# fpb register map
Vendor: Texas Instruments
Peripheral module from a debugger description file (folder MSP432).
Registers are 32-bit, read-write, no defined reset value unless marked. A register's access mark holds for its fields unless they carry their own. Offsets are as the file gives them; lines under a group give offsets from that group; [hi:lo] are bit positions; {n}, {i} and the like mark numbered series; 'fields as' and 'values as' point back to an identical list; <NAME> marks a mode.

## FPB
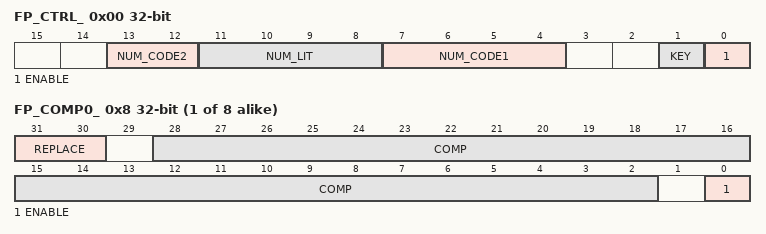
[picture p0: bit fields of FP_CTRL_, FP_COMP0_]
0x00 FP_CTRL_ — Flash Patch Control Register
  [13:12] NUM_CODE2 — Number of full banks of code comparators, sixteen comparators p
  [11:8] NUM_LIT — Number of literal slots field.
    0=NUM_LIT__0 (no literal slots); 2=NUM_LIT__2 (two literal slots)
  [7:4] NUM_CODE1 — Number of code slots field.
    0=NUM_CODE1__0 (no code slots); 2=NUM_CODE1__2 (two code slots); 6=NUM_CODE1__6 (six code slots)
  [1] KEY
  [0] ENABLE — Flash patch unit enable bit
    0=ENABLE__0 (flash patch unit disabled); 1=ENABLE__1 (flash patch unit enabled)
0x04 FP_REMAP_ — Flash Patch Remap Register
  [28:5] REMAP — Remap base address field.
{0x8+4i} FP_COMP{i}_ (i=0..7) — Flash Patch Comparator Registers
  [31:30] REPLACE — This selects what happens when the COMP address is matched
    0=REPLACE__0 (remap to remap address. See FP_REMAP); 1=REPLACE__1 (set BKPT on lower halfword, upper is unaffected); 2=REPLACE__2 (set BKPT on upper halfword, lower is unaffected); 3=REPLACE__3 (set BKPT on both lower and upper halfwords.)
  [28:2] COMP — Comparison address.
  [0] ENABLE — Compare and remap enable for Flash Patch Comparator Register {i}
    0=ENABLE__0 (Flash Patch Comparator Register {i} compare and remap disabled); 1=ENABLE__1 (Flash Patch Comparator Register {i} compare and remap enabled)
